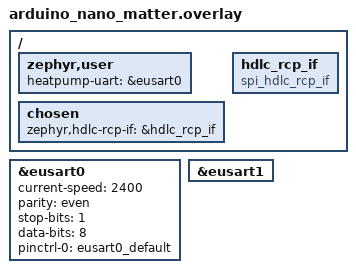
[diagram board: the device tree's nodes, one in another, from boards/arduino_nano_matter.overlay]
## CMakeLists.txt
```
# SPDX-License-Identifier: Apache-2.0

cmake_minimum_required(VERSION 3.20.0)

# Find Zephyr. This also loads Zephyr's build system.
find_package(Zephyr REQUIRED HINTS $ENV{ZEPHYR_BASE})

project(matter_cn105_controller VERSION 0.1.0)

# Add application source files
target_sources(app PRIVATE
    lib/HeatPump/heat_pump.h
    lib/HeatPump/heat_pump.cpp
    src/main.c
    src/heatpump_driver.cpp
    src/matter_integration.cpp
    src/state_sync.cpp
    src/attribute_handlers.cpp
    src/ot_error_stub.cpp
)

# Add include directories
target_include_directories(app PRIVATE
    include
    src
)

# TODO: Add Matter SDK library when integrating
# TODO: Add any additional dependencies
```

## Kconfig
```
# SPDX-License-Identifier: GPL-3.0-or-later
# Kconfig - Matter CN105 Heat Pump Controller configuration options

mainmenu "Matter CN105 Heat Pump Controller Configuration"

config APP_HEATPUMP_CN105
	bool "Enable CN105 Heat Pump Controller"
	default y
	help
	  Enable Mitsubishi heat pump controller via CN105 interface

if APP_HEATPUMP_CN105

config APP_HEATPUMP_UART_DEVICE
	string "UART device name for CN105"
	default "UART_1"
	help
	  UART device name for CN105 communication

config APP_HEATPUMP_SYNC_INTERVAL_MS
	int "Heat pump sync interval in milliseconds"
	default 5000
	help
	  Interval for syncing with heat pump

config APP_MATTER_ENABLED
	bool "Enable Matter integration"
	default y
	help
	  Enable Matter/CHIP protocol integration

endif # APP_HEATPUMP_CN105

source "Kconfig.zephyr"
```

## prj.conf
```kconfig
# SPDX-License-Identifier: Apache-2.0

# Zephyr Kernel Configuration
CONFIG_HEAP_MEM_POOL_SIZE=16384
CONFIG_MAIN_STACK_SIZE=2048
CONFIG_SYSTEM_WORKQUEUE_STACK_SIZE=2048

# Logging Configuration
CONFIG_LOG=y
CONFIG_LOG_DEFAULT_LEVEL=3
CONFIG_LOG_PRINTK=y
CONFIG_LOG_MODE_IMMEDIATE=y

CONFIG_LOG_MAX_LEVEL=1
CONFIG_LOG_MODE_MINIMAL=n
CONFIG_LOG_BACKEND_SPINEL=y
CONFIG_LOG_BACKEND_RTT=y
CONFIG_LOG_BACKEND_UART=n
CONFIG_BOOT_BANNER=n

# Serial/UART Configuration for CN105
CONFIG_SERIAL=y
CONFIG_UART_INTERRUPT_DRIVEN=y
CONFIG_UART_LINE_CTRL=y

# C++ Support
CONFIG_CPP=y
CONFIG_NEWLIB_LIBC=y

# Networking (for Matter/Thread)
CONFIG_NETWORKING=y
CONFIG_NET_IPV6=y
CONFIG_NET_UDP=y
CONFIG_NET_TCP=y
CONFIG_NET_L2_OPENTHREAD=y

# Disable certain parts of Zephyr IPv6 stack
CONFIG_NET_IPV6_NBR_CACHE=n
CONFIG_NET_IPV6_MLD=n

# Use HDLC RCP interface (host mode) for OpenThread
CONFIG_HDLC_RCP_IF=y
CONFIG_HDLC_RCP_IF_UART=y
CONFIG_OPENTHREAD_HDLC_RCP_IF_UART_RX_RING_BUFFER_SIZE=1024
CONFIG_OPENTHREAD_HDLC_RCP_IF_UART_TX_RING_BUFFER_SIZE=1024

# Basic OpenThread settings for quick bring-up
CONFIG_NET_CONFIG_SETTINGS=y
CONFIG_NET_CONFIG_IEEE802154_CHANNEL=26
CONFIG_NET_CONFIG_IEEE802154_PAN_ID=0x1234


# Optional: OT shell for debugging
# Uncomment if you want CLI at the Zephyr shell
# CONFIG_SHELL=y
# CONFIG_NET_SHELL=y
# CONFIG_OPENTHREAD_SHELL=y

# Thread Configuration (for Matter)
# TODO: Enable when Matter SDK is integrated
# CONFIG_NET_L2_OPENTHREAD=y
# CONFIG_OPENTHREAD_NORDIC_LIBRARY=y

# Matter SDK Configuration
# TODO: Enable when Matter SDK is integrated
# CONFIG_CHIP=y
# CONFIG_CHIP_PROJECT_CONFIG="matter_config.h"
# CONFIG_CHIP_DEVICE_VENDOR_ID=0xFFF1
# CONFIG_CHIP_DEVICE_PRODUCT_ID=0x8001

# Flash and Storage (for Matter credentials)
CONFIG_FLASH=y
CONFIG_FLASH_PAGE_LAYOUT=y
CONFIG_FLASH_MAP=y
CONFIG_NVS=y
CONFIG_SETTINGS=y
CONFIG_SETTINGS_NVS=y

# Increase memory for Matter stack
CONFIG_IDLE_STACK_SIZE=1024
CONFIG_ISR_STACK_SIZE=2048

# Debugging
CONFIG_DEBUG=y
CONFIG_THREAD_NAME=y
CONFIG_THREAD_MONITOR=y

# Console
CONFIG_CONSOLE=y
CONFIG_UART_CONSOLE=y

# Enable asserts for development
CONFIG_ASSERT=y
CONFIG_ASSERT_LEVEL=2
```

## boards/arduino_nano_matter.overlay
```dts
// SPDX-License-Identifier: GPL-3.0-or-later
/*
 * Device tree overlay for Arduino Nano Matter
 * Configures UART for CN105 heat pump communication
 */

/ {
	zephyr,user {
		heatpump-uart = &eusart0;
	};

	/* OpenThread HDLC RCP interface selection */
	chosen {
		/* Select the HDLC RCP network interface device */
		zephyr,hdlc-rcp-if = &hdlc_rcp_if;
	};

	/* Define the HDLC RCP interface device (SPI-based SPINEL) */
	hdlc_rcp_if: hdlc_rcp_if {
		compatible = "spi_hdlc_rcp_if";
		status = "okay";
	};
};

/* Configure UART for CN105 communication
 * Baud: 2400, 8 data bits, even parity, 1 stop bit (8E1)
 * Wired to Arduino UART0: TX=PA4 (D0), RX=PA5 (D1)
 */
&eusart0 {
	status = "okay";
	current-speed = <2400>;
	parity = "even";
	stop-bits = "1";
	data-bits = <8>;
	pinctrl-0 = <&eusart0_default>;
	pinctrl-names = "default";
};

/* Configure SPI for OpenThread RCP (SPINEL protocol)
 * Uses eusart1 as SPI bus with 4 MHz clock
 * CS: PC7 (active low)
 * Clock, MOSI, MISO: pins defined in eusart1_default pinctrl
 */
&eusart1 {
	status = "okay";
};
```

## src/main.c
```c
/**
 * @file main.c
 * @brief Main entry point for Matter CN105 Heat Pump Controller
 * 
 * This is the main application entry point for the Zephyr-based
 * Matter controller for Mitsubishi heat pumps via CN105 interface.
 */

#include <zephyr/kernel.h>
#include <zephyr/logging/log.h>
#include "heatpump_driver.h"

LOG_MODULE_REGISTER(main, CONFIG_LOG_DEFAULT_LEVEL);

/**
 * @brief Main application entry point
 * 
 * Initializes all subsystems:
 * - Heat pump driver (UART communication)
 * - Matter stack
 * - State synchronization
 * 
 * @return 0 on success, negative errno on failure
 */
int main(void)
{
    LOG_INF("Matter CN105 Heat Pump Controller starting...");
    LOG_INF("Version: 0.1.0");
    
    /* Initialize heat pump driver */
    LOG_INF("Initializing heat pump driver...");
    int ret = heatpump_init();
    if (ret) {
        LOG_ERR("heatpump_init failed: %d", ret);
    }
    ret = heatpump_connect();
    if (ret) {
        LOG_WRN("heatpump_connect pending/not ready: %d", ret);
    }
    
    /* TODO: Initialize Matter stack */
    LOG_INF("Initializing Matter stack...");
    
    /* TODO: Start state synchronization */
    LOG_INF("Starting state synchronization...");
    
    LOG_INF("Initialization complete");
    
    /* Main loop - handle events and maintain state sync */
    while (1) {
        /* Maintain CN105 link */
        heatpump_sync();
        
        /* Optionally, log status periodically */
        if (heatpump_is_connected()) {
            heatpump_status_t status;
            if (heatpump_get_status(&status) == 0) {
                LOG_DBG("HP: room=%.1fC operating=%d freq=%d",
                        (double)status.roomTemperature,
                        status.operating,
                        status.compressorFrequency);
            }
        }
        /* TODO: Process Matter attribute changes */
        /* TODO: Synchronize state between heat pump and Matter */
        
        k_sleep(K_MSEC(100));
    }
    
    return 0;
}
```

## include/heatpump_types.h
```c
/**
 * @file heatpump_types.h
 * @brief Data structures for Mitsubishi heat pump control
 * 
 * Based on the SwiCago/HeatPump library data structures
 * Adapted for use with Zephyr RTOS and Matter integration
 * 
 * Original library: https://github.com/SwiCago/HeatPump
 * License: GPL-3.0
 */

#ifndef HEATPUMP_TYPES_H
#define HEATPUMP_TYPES_H

#include <stdbool.h>

#ifdef __cplusplus
extern "C" {
#endif

/**
 * @brief Heat pump settings structure
 * 
 * Contains all user-configurable settings for the heat pump
 */
typedef struct {
    const char* power;        /**< Power state: "ON", "OFF" */
    const char* mode;         /**< Operating mode: "HEAT", "DRY", "COOL", "FAN", "AUTO" */
    float temperature;        /**< Target temperature in Celsius (16-31°C) */
    const char* fan;          /**< Fan speed: "AUTO", "QUIET", "1", "2", "3", "4" */
    const char* vane;         /**< Vertical vane position: "AUTO", "1", "2", "3", "4", "5", "SWING" */
    const char* wideVane;     /**< Horizontal vane position: "<<", "<", "|", ">", ">>", "<>", "SWING" */
    bool iSee;               /**< i-See sensor enabled/disabled */
    bool connected;          /**< Connection status with heat pump */
} heatpump_settings_t;

/**
 * @brief Heat pump status structure
 * 
 * Contains read-only status information from the heat pump
 */
typedef struct {
    float roomTemperature;       /**< Current room temperature in Celsius */
    bool operating;              /**< True if heat pump is actively heating/cooling */
    int compressorFrequency;     /**< Compressor frequency in Hz (0 when off) */
} heatpump_status_t;

/**
 * @brief Heat pump timers structure
 * 
 * Contains timer settings and status
 */
typedef struct {
    const char* mode;            /**< Timer mode: "NONE", "OFF", "ON", "BOTH" */
    int onMinutesSet;           /**< Minutes until ON timer activates (0 if not set) */
    int onMinutesRemaining;     /**< Minutes remaining for ON timer */
    int offMinutesSet;          /**< Minutes until OFF timer activates (0 if not set) */
    int offMinutesRemaining;    /**< Minutes remaining for OFF timer */
} heatpump_timers_t;

/**
 * @brief Heat pump operating modes enumeration
 */
typedef enum {
    HP_MODE_HEAT = 0,
    HP_MODE_DRY,
    HP_MODE_COOL,
    HP_MODE_FAN,
    HP_MODE_AUTO
} heatpump_mode_e;

/**
 * @brief Fan speed enumeration
 */
typedef enum {
    HP_FAN_AUTO = 0,
    HP_FAN_QUIET,
    HP_FAN_1,
    HP_FAN_2,
    HP_FAN_3,
    HP_FAN_4
} heatpump_fan_e;

/**
 * @brief Vane position enumeration
 */
typedef enum {
    HP_VANE_AUTO = 0,
    HP_VANE_1,
    HP_VANE_2,
    HP_VANE_3,
    HP_VANE_4,
    HP_VANE_5,
    HP_VANE_SWING
} heatpump_vane_e;

/**
 * @brief Wide vane (horizontal) position enumeration
 */
typedef enum {
    HP_WIDE_VANE_FAR_LEFT = 0,    /**< "<<" */
    HP_WIDE_VANE_LEFT,             /**< "<" */
    HP_WIDE_VANE_CENTER,           /**< "|" */
    HP_WIDE_VANE_RIGHT,            /**< ">" */
    HP_WIDE_VANE_FAR_RIGHT,        /**< ">>" */
    HP_WIDE_VANE_WIDE,             /**< "<>" */
    HP_WIDE_VANE_SWING             /**< "SWING" */
} heatpump_wide_vane_e;

/**
 * @brief Temperature limits
 */
#define HP_TEMP_MIN 16.0f
#define HP_TEMP_MAX 31.0f

/**
 * @brief Serial communication parameters for CN105
 */
#define HP_UART_BAUD_RATE 2400
#define HP_UART_DATA_BITS 8
#define HP_UART_PARITY_EVEN 1
#define HP_UART_STOP_BITS 1

#ifdef __cplusplus
}
#endif

#endif /* HEATPUMP_TYPES_H */
```

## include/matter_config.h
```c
/**
 * @file matter_config.h
 * @brief Matter/CHIP configuration for heat pump controller
 * 
 * Defines Matter cluster IDs, device types, and configuration
 * for integration with the Matter smart home protocol
 */

#ifndef MATTER_CONFIG_H
#define MATTER_CONFIG_H

#ifdef __cplusplus
extern "C" {
#endif

/**
 * @brief Matter Device Type
 * 
 * The heat pump is exposed as a Thermostat device type
 */
#define MATTER_DEVICE_TYPE_THERMOSTAT 0x0301

/**
 * @brief Standard Matter Cluster IDs
 */
#define MATTER_CLUSTER_IDENTIFY         0x0003  /**< Identify cluster */
#define MATTER_CLUSTER_ON_OFF           0x0006  /**< On/Off cluster */
#define MATTER_CLUSTER_DESCRIPTOR       0x001D  /**< Descriptor cluster */
#define MATTER_CLUSTER_THERMOSTAT       0x0201  /**< Thermostat cluster */
#define MATTER_CLUSTER_FAN_CONTROL      0x0202  /**< Fan Control cluster */
#define MATTER_CLUSTER_TEMP_MEASUREMENT 0x0402  /**< Temperature Measurement cluster */

/**
 * @brief Custom Vendor-Specific Cluster IDs
 * 
 * These clusters provide access to Mitsubishi-specific features
 * not available in standard Matter clusters.
 * 
 * Vendor ID range: 0xFFF1XXXX (example vendor ID)
 */
#define MATTER_CLUSTER_VANE_CONTROL     0xFFF1FC01  /**< Vertical vane control */
#define MATTER_CLUSTER_WIDE_VANE_CONTROL 0xFFF1FC02 /**< Horizontal vane control */
#define MATTER_CLUSTER_HP_STATUS        0xFFF1FC03  /**< Heat pump status information */
#define MATTER_CLUSTER_ISEE_CONTROL     0xFFF1FC04  /**< i-See sensor control */

/**
 * @brief Thermostat Cluster Attributes
 */
#define MATTER_ATTR_LOCAL_TEMPERATURE           0x0000  /**< Current room temperature */
#define MATTER_ATTR_OCCUPIED_COOLING_SETPOINT   0x0011  /**< Cooling setpoint */
#define MATTER_ATTR_OCCUPIED_HEATING_SETPOINT   0x0012  /**< Heating setpoint */
#define MATTER_ATTR_SYSTEM_MODE                 0x001C  /**< System mode (off/heat/cool/auto) */
#define MATTER_ATTR_THERMOSTAT_RUNNING_STATE    0x0029  /**< Running state */

/**
 * @brief Fan Control Cluster Attributes
 */
#define MATTER_ATTR_FAN_MODE                    0x0000  /**< Fan mode */
#define MATTER_ATTR_FAN_MODE_SEQUENCE           0x0001  /**< Fan mode sequence */
#define MATTER_ATTR_PERCENT_SETTING             0x0002  /**< Fan speed percentage */
#define MATTER_ATTR_PERCENT_CURRENT             0x0003  /**< Current fan speed percentage */

/**
 * @brief Thermostat System Mode Values
 */
#define MATTER_THERMOSTAT_MODE_OFF      0x00
#define MATTER_THERMOSTAT_MODE_AUTO     0x01
#define MATTER_THERMOSTAT_MODE_COOL     0x03
#define MATTER_THERMOSTAT_MODE_HEAT     0x04
#define MATTER_THERMOSTAT_MODE_DRY      0x08  /**< Precool/Dehumidify */
#define MATTER_THERMOSTAT_MODE_FAN_ONLY 0x07

/**
 * @brief Fan Mode Values
 */
#define MATTER_FAN_MODE_OFF    0x00
#define MATTER_FAN_MODE_LOW    0x01
#define MATTER_FAN_MODE_MEDIUM 0x02
#define MATTER_FAN_MODE_HIGH   0x03
#define MATTER_FAN_MODE_ON     0x04
#define MATTER_FAN_MODE_AUTO   0x05
#define MATTER_FAN_MODE_SMART  0x06

/**
 * @brief Matter Endpoint Configuration
 */
#define MATTER_ENDPOINT_ROOT        0   /**< Root endpoint */
#define MATTER_ENDPOINT_THERMOSTAT  1   /**< Thermostat endpoint */

/**
 * @brief Temperature Conversion Macros
 * 
 * Matter uses temperature in units of 0.01°C (hundredths of degrees)
 */
#define CELSIUS_TO_MATTER_TEMP(temp) ((int16_t)((temp) * 100))
#define MATTER_TEMP_TO_CELSIUS(temp) ((float)(temp) / 100.0f)

/**
 * @brief Default Configuration Values
 */
#define DEFAULT_MIN_SETPOINT_CELSIUS    16.0f   /**< Minimum temperature setpoint */
#define DEFAULT_MAX_SETPOINT_CELSIUS    31.0f   /**< Maximum temperature setpoint */
#define DEFAULT_SETPOINT_CELSIUS        22.0f   /**< Default temperature setpoint */

/**
 * @brief Matter Stack Configuration
 * 
 * TODO: These values need to be tuned based on actual testing
 */
#define MATTER_THREAD_STACK_SIZE    4096    /**< Matter task stack size */
#define MATTER_THREAD_PRIORITY      5       /**< Matter task priority */

/**
 * @brief Update Intervals (milliseconds)
 */
#define HP_STATUS_UPDATE_INTERVAL_MS    5000    /**< Status polling interval */
#define HP_SETTINGS_UPDATE_INTERVAL_MS  1000    /**< Settings update interval */

/* Configuration placeholders for future implementation */
/* TODO: Implement actual Matter integration */
/* TODO: Add commissioning configuration */
/* TODO: Add network credential storage configuration */
/* TODO: Add OTA update configuration */
/* TODO: Add factory reset configuration */

#ifdef __cplusplus
}
#endif

#endif /* MATTER_CONFIG_H */
```

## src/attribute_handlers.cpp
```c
/**
 * @file attribute_handlers.cpp
 * @brief Matter attribute read/write handlers
 * 
 * Handles Matter cluster attribute operations and converts
 * between Matter data formats and heat pump formats.
 */

#include <zephyr/kernel.h>
#include <zephyr/logging/log.h>
#include "matter_config.h"
#include "heatpump_driver.h"

LOG_MODULE_REGISTER(attribute_handlers, CONFIG_LOG_DEFAULT_LEVEL);

/**
 * @brief Handle thermostat system mode attribute write
 * 
 * Converts Matter thermostat mode to heat pump mode and applies
 */
int handle_thermostat_mode_write(uint8_t mode)
{
    const char *hp_mode = NULL;
    
    /* Convert Matter mode to heat pump mode */
    switch (mode) {
        case MATTER_THERMOSTAT_MODE_OFF:
            return heatpump_set_power("OFF");
        
        case MATTER_THERMOSTAT_MODE_HEAT:
            hp_mode = "HEAT";
            break;
        
        case MATTER_THERMOSTAT_MODE_COOL:
            hp_mode = "COOL";
            break;
        
        case MATTER_THERMOSTAT_MODE_AUTO:
            hp_mode = "AUTO";
            break;
        
        case MATTER_THERMOSTAT_MODE_DRY:
            hp_mode = "DRY";
            break;
        
        case MATTER_THERMOSTAT_MODE_FAN_ONLY:
            hp_mode = "FAN";
            break;
        
        default:
            LOG_ERR("Unsupported thermostat mode: %d", mode);
            return -EINVAL;
    }
    
    /* Ensure power is on */
    heatpump_set_power("ON");
    
    /* Set the mode */
    return heatpump_set_mode(hp_mode);
}

/**
 * @brief Handle temperature setpoint attribute write
 * 
 * Converts Matter temperature (0.01°C units) to Celsius
 */
int handle_temperature_setpoint_write(int16_t matter_temp)
{
    float celsius = MATTER_TEMP_TO_CELSIUS(matter_temp);
    
    /* Validate temperature range */
    if (celsius < HP_TEMP_MIN || celsius > HP_TEMP_MAX) {
        LOG_ERR("Temperature out of range: %.1f°C", static_cast<double>(celsius));
        return -EINVAL;
    }
    
    return heatpump_set_temperature(celsius);
}

/**
 * @brief Handle fan mode attribute write
 * 
 * Converts Matter fan mode to heat pump fan setting
 */
int handle_fan_mode_write(uint8_t mode)
{
    const char *hp_fan = NULL;
    
    /* Convert Matter fan mode to heat pump fan */
    switch (mode) {
        case MATTER_FAN_MODE_OFF:
            hp_fan = "QUIET";  /* Map OFF to QUIET */
            break;
        
        case MATTER_FAN_MODE_LOW:
            hp_fan = "1";
            break;
        
        case MATTER_FAN_MODE_MEDIUM:
            hp_fan = "2";
            break;
        
        case MATTER_FAN_MODE_HIGH:
            hp_fan = "4";
            break;
        
        case MATTER_FAN_MODE_AUTO:
            hp_fan = "AUTO";
            break;
        
        default:
            LOG_ERR("Unsupported fan mode: %d", mode);
            return -EINVAL;
    }
    
    return heatpump_set_fan(hp_fan);
}

/**
 * @brief Read thermostat local temperature attribute
 * 
 * Returns current room temperature from heat pump
 */
int handle_local_temperature_read(int16_t *matter_temp)
{
    heatpump_status_t status;
    
    if (heatpump_get_status(&status) != 0) {
        return -EIO;
    }
    
    *matter_temp = CELSIUS_TO_MATTER_TEMP(status.roomTemperature);
    return 0;
}

/**
 * @brief Read thermostat running state attribute
 * 
 * Returns whether heat pump is actively heating/cooling
 */
int handle_running_state_read(uint16_t *state)
{
    heatpump_status_t status;
    
    if (heatpump_get_status(&status) != 0) {
        return -EIO;
    }
    
    /* TODO: Map heat pump operating state to Matter running state bits */
    *state = status.operating ? 0x0001 : 0x0000;
    
    return 0;
}

/**
 * @brief Handle custom vane control attribute write
 * 
 * Controls vertical vane position
 */
int handle_vane_position_write(uint8_t position)
{
    const char *vane = NULL;
    
    /* Map position to vane string */
    switch (position) {
        case 0: vane = "AUTO"; break;
        case 1: vane = "1"; break;
        case 2: vane = "2"; break;
        case 3: vane = "3"; break;
        case 4: vane = "4"; break;
        case 5: vane = "5"; break;
        case 6: vane = "SWING"; break;
        default:
            LOG_ERR("Invalid vane position: %d", position);
            return -EINVAL;
    }
    
    return heatpump_set_vane(vane);
}

/**
 * @brief Handle custom wide vane control attribute write
 * 
 * Controls horizontal vane position
 */
int handle_wide_vane_position_write(uint8_t position)
{
    const char *wide_vane = NULL;
    
    /* Map position to wide vane string */
    switch (position) {
        case 0: wide_vane = "<<"; break;
        case 1: wide_vane = "<"; break;
        case 2: wide_vane = "|"; break;
        case 3: wide_vane = ">"; break;
        case 4: wide_vane = ">>"; break;
        case 5: wide_vane = "<>"; break;
        case 6: wide_vane = "SWING"; break;
        default:
            LOG_ERR("Invalid wide vane position: %d", position);
            return -EINVAL;
    }
    
    return heatpump_set_wide_vane(wide_vane);
}
```

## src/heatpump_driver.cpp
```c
/**
 * @file heatpump_driver.cpp
 * @brief Heat pump driver implementation for CN105 communication
 * 
 * This file will contain the adaptation of the SwiCago/HeatPump library
 * for use with Zephyr RTOS.
 * 
 * Original library: https://github.com/SwiCago/HeatPump
 * License: GPL-3.0
 */

#include "heatpump_driver.h"
#include <zephyr/kernel.h>
#include <zephyr/drivers/uart.h>
#include <zephyr/device.h>
#include <zephyr/devicetree.h>
#include "../lib/HeatPump/heat_pump.h"
#include <zephyr/logging/log.h>

LOG_MODULE_REGISTER(heatpump_driver, CONFIG_LOG_DEFAULT_LEVEL);

/* Thread configuration */
#define HEATPUMP_THREAD_STACK_SIZE 2048
#define HEATPUMP_THREAD_PRIORITY   5
#define HEATPUMP_UPDATE_INTERVAL_MS 100  /* Poll heat pump every 100ms */

/* Memory slab configuration for packet buffers */
#define PACKET_BUFFER_SIZE  64  /* Max packet size is 22 bytes, rounded to 64 for alignment */
#define NUM_PACKET_BUFFERS  4   /* Pre-allocate 4 packet buffers for concurrent operations */

/**
 * @brief Packet buffer structure for memory slab
 *
 * Provides a predictable memory layout for efficient allocation.
 */
struct packet_buffer {
    uint8_t data[PACKET_BUFFER_SIZE];
    size_t length;
};

/* Define and initialize the packet buffer memory slab */
K_MEM_SLAB_DEFINE(packet_slab, sizeof(struct packet_buffer), NUM_PACKET_BUFFERS, 4);

/* Static variables for driver state */
static heatpump_settings_t current_settings;
static heatpump_status_t current_status;
static heatpump_timers_t current_timers;
static bool connected = false;

/* Callback functions */
static heatpump_settings_callback_t settings_callback = NULL;
static heatpump_status_callback_t status_callback = NULL;

/* UART device (assigned when CN105 transport is implemented) */
static const struct device *uart_dev;
static HeatPump s_hp;

/* Thread management */
static struct k_thread heatpump_thread_data;
static k_tid_t heatpump_thread_id = NULL;
static bool heatpump_thread_running = false;
static K_THREAD_STACK_DEFINE(heatpump_stack, HEATPUMP_THREAD_STACK_SIZE);

/* Forward declarations for HeatPump library callbacks */
static void hp_on_connect_callback(void);
static void hp_settings_changed_callback(void);
static void hp_status_changed_callback(heatpumpStatus newStatus);
static void hp_packet_callback(uint8_t* packet, unsigned int length, char* packetDirection);
static void hp_room_temp_changed_callback(float currentRoomTemperature);
/**
 * @brief HeatPump library callback: Connection established
 * 
 * Called when the heat pump handshake is successful
 */
static void hp_on_connect_callback(void)
{
    LOG_INF("Heat pump connected");
    connected = true;
}

/**
 * @brief HeatPump library callback: Settings changed
 * 
 * Called when the heat pump settings change
 */
static void hp_settings_changed_callback(void)
{
    LOG_INF("Heat pump settings changed");
    
    /* Update local cache */
    heatpumpSettings hp = s_hp.getSettings();
    current_settings.power = hp.power;
    current_settings.mode = hp.mode;
    current_settings.temperature = hp.temperature;
    current_settings.fan = hp.fan;
    current_settings.vane = hp.vane;
    current_settings.wideVane = hp.wideVane;
    current_settings.iSee = hp.iSee;
    current_settings.connected = connected;
    
    /* Call registered application callback if present */
    if (settings_callback) {
        settings_callback(current_settings);
    }
}

/**
 * @brief HeatPump library callback: Status changed
 * 
 * Called when the heat pump status changes
 * 
 * @param newStatus The new status from the heat pump
 */
static void hp_status_changed_callback(heatpumpStatus newStatus)
{
    LOG_INF("Heat pump status changed");
    
    /* Update local cache */
    current_status.roomTemperature = newStatus.roomTemperature;
    current_status.operating = newStatus.operating;
    current_status.compressorFrequency = newStatus.compressorFrequency;
    
    /* Update timers as well */
    current_timers.mode = newStatus.timers.mode;
    current_timers.onMinutesSet = newStatus.timers.onMinutesSet;
    current_timers.onMinutesRemaining = newStatus.timers.onMinutesRemaining;
    current_timers.offMinutesSet = newStatus.timers.offMinutesSet;
    current_timers.offMinutesRemaining = newStatus.timers.offMinutesRemaining;
    
    /* Call registered application callback if present */
    if (status_callback) {
        status_callback(current_status);
    }
}

/**
 * @brief HeatPump library callback: Packet transmitted or received
 * 
 * Called for debug/logging purposes when packets are sent or received
 * 
 * @param packet The packet data
 * @param length The packet length
 * @param packetDirection Direction indicator ("packetSent" or "packetRecv")
 */
static void hp_packet_callback(uint8_t* packet, unsigned int length, char* packetDirection)
{
    if (packet && length > 0 && packetDirection) {
        LOG_DBG("Heat pump packet %s: %d bytes", packetDirection, length);
        /* Could log hex dump here for deeper debugging if needed */
    }
}

/**
 * @brief HeatPump library callback: Room temperature changed
 * 
 * Called when the room temperature reading changes
 * 
 * @param currentRoomTemperature The new room temperature
 */
static void hp_room_temp_changed_callback(float currentRoomTemperature)
{
    LOG_INF("Room temperature: %.1f°C", (double)currentRoomTemperature);
    current_status.roomTemperature = currentRoomTemperature;
    
    /* Call registered application callback if present */
    if (status_callback) {
        status_callback(current_status);
    }
}

/**
 * @brief Heatpump update thread
 * 
 * This thread runs periodically to:
 * - Transmit pending commands to the heat pump
 * - Read responses from the heat pump
 * - Invoke callbacks when state changes occur
 * 
 * This replaces the Arduino loop() paradigm with Zephyr threading
 * 
 * @param arg1 Unused argument (required by k_thread_create)
 * @param arg2 Unused argument (required by k_thread_create)
 * @param arg3 Unused argument (required by k_thread_create)
 */
static void heatpump_update_thread(void *arg1, void *arg2, void *arg3)
{
    ARG_UNUSED(arg1);
    ARG_UNUSED(arg2);
    ARG_UNUSED(arg3);
    
    LOG_INF("Heat pump update thread started");
    heatpump_thread_running = true;
    
    /* Main update loop */
    while (heatpump_thread_running) {
        /* Call the HeatPump library's update method */
        /* This method handles:
         * - Sending queued commands
         * - Reading responses
         * - Triggering registered callbacks
         */
        if (s_hp.update()) {
            /* Update was successful */
            LOG_DBG("Heat pump update completed");
        }
        
        /* Sleep for the configured update interval */
        k_msleep(HEATPUMP_UPDATE_INTERVAL_MS);
    }
    
    LOG_INF("Heat pump update thread stopped");
}

/**

 * @brief Initialize the heat pump driver
 */
int heatpump_init(void)
{
    LOG_INF("Initializing heat pump driver");
    
#if DT_HAS_CHOSEN(heatpump_uart)
    uart_dev = DEVICE_DT_GET(DT_CHOSEN(heatpump_uart));
#else
    uart_dev = DEVICE_DT_GET(DT_NODELABEL(eusart0));
#endif
    if (!device_is_ready(uart_dev)) {
        LOG_ERR("Heatpump UART device not ready");
        return -ENODEV;
    }
    if (!s_hp.connect(uart_dev, HP_UART_BAUD_RATE)) {
        LOG_ERR("Heat pump handshake failed");
        return -EIO;
    }
    connected = s_hp.isConnected();
    
    /* Initialize settings to default values */
    current_settings.power = "OFF";
    current_settings.mode = "AUTO";
    current_settings.temperature = 22.0f;
    current_settings.fan = "AUTO";
    current_settings.vane = "AUTO";
    current_settings.wideVane = "|";
    current_settings.iSee = false;
    current_settings.connected = false;
    
    /* Initialize status */
    current_status.roomTemperature = 20.0f;
    current_status.operating = false;
    current_status.compressorFrequency = 0;
    
    /* Initialize timers */
    current_timers.mode = "NONE";
    current_timers.onMinutesSet = 0;
    current_timers.onMinutesRemaining = 0;
    current_timers.offMinutesSet = 0;
    current_timers.offMinutesRemaining = 0;
    
    /* Register HeatPump library callbacks for Zephyr integration */
    s_hp.setOnConnectCallback(hp_on_connect_callback);
    s_hp.setSettingsChangedCallback(hp_settings_changed_callback);
    s_hp.setStatusChangedCallback(hp_status_changed_callback);
    s_hp.setPacketCallback(hp_packet_callback);
    s_hp.setRoomTempChangedCallback(hp_room_temp_changed_callback);
    
    /* Start the heat pump update thread */
    heatpump_thread_id = k_thread_create(&heatpump_thread_data,
                                         heatpump_stack,
                                         HEATPUMP_THREAD_STACK_SIZE,
                                         heatpump_update_thread,
                                         NULL, NULL, NULL,
                                         HEATPUMP_THREAD_PRIORITY,
                                         0,
                                         K_NO_WAIT);
    
    if (heatpump_thread_id == NULL) {
        LOG_ERR("Failed to create heat pump update thread");
        return -EAGAIN;
    }
    
    k_thread_name_set(heatpump_thread_id, "heatpump");
    
    LOG_INF("Heat pump driver initialized");
    return 0;
}

/**
 * @brief Shutdown the heat pump driver
 *
 * Stops the update thread and cleans up resources
 *
 * @return 0 on success, negative errno on failure
 */
int heatpump_shutdown(void)
{
    LOG_INF("Shutting down heat pump driver");
    
    if (heatpump_thread_id != NULL) {
        /* Signal the thread to stop */
        heatpump_thread_running = false;
        
        /* Wait for thread to complete (with timeout) */
        int ret = k_thread_join(heatpump_thread_id, K_MSEC(5000));
        if (ret != 0) {
            LOG_WRN("Heat pump thread did not exit cleanly, forcing abort");
            k_thread_abort(heatpump_thread_id);
        }
        
        heatpump_thread_id = NULL;
    }
    
    LOG_INF("Heat pump driver shutdown complete");
    return 0;
}

/**
 * @brief Connect to the heat pump
 */
int heatpump_connect(void)
{
    LOG_INF("Connecting to heat pump...");
    if (!device_is_ready(uart_dev)) {
        return -ENODEV;
    }
    if (!s_hp.connect(uart_dev, HP_UART_BAUD_RATE)) {
        return -EIO;
    }
    connected = s_hp.isConnected();
    return connected ? 0 : -EIO;
}

/**
 * @brief Synchronize with the heat pump
 */
void heatpump_sync(void)
{
    s_hp.sync();
}

/**
 * @brief Get current heat pump settings
 */
int heatpump_get_settings(heatpump_settings_t *settings)
{
    if (settings == NULL) {
        return -EINVAL;
    }
    heatpumpSettings hp = s_hp.getSettings();
    settings->power = hp.power;
    settings->mode = hp.mode;
    settings->temperature = hp.temperature;
    settings->fan = hp.fan;
    settings->vane = hp.vane;
    settings->wideVane = hp.wideVane;
    settings->iSee = hp.iSee;
    settings->connected = connected;
    return 0;
}

/**
 * @brief Get current heat pump status
 */
int heatpump_get_status(heatpump_status_t *status)
{
    if (status == NULL) {
        return -EINVAL;
    }
    heatpumpStatus s = s_hp.getStatus();
    status->roomTemperature = s.roomTemperature;
    status->operating = s.operating;
    status->compressorFrequency = s.compressorFrequency;
    return 0;
}

/**
 * @brief Get current heat pump timers
 */
int heatpump_get_timers(heatpump_timers_t *timers)
{
    if (timers == NULL) {
        return -EINVAL;
    }
    /* The library exposes timers via getStatus parsing; no direct method */
    heatpumpStatus s = s_hp.getStatus();
    (void)s;
    *timers = current_timers;
    return 0;
}

/**
 * @brief Set power state
 */
int heatpump_set_power(const char *power)
{
    LOG_INF("Setting power: %s", power);
    s_hp.setPowerSetting((power && power[0] == 'O' && power[1] == 'N') ? true : false);
    return s_hp.update() ? 0 : -EIO;
}

/**
 * @brief Set operating mode
 */
int heatpump_set_mode(const char *mode)
{
    LOG_INF("Setting mode: %s", mode);
    s_hp.setModeSetting(mode);
    return s_hp.update() ? 0 : -EIO;
}

/**
 * @brief Set target temperature
 */
int heatpump_set_temperature(float temperature)
{
    LOG_INF("Setting temperature: %.1f°C", (double)temperature);
    s_hp.setTemperature(temperature);
    return s_hp.update() ? 0 : -EIO;
}

/**
 * @brief Set fan speed
 */
int heatpump_set_fan(const char *fan)
{
    LOG_INF("Setting fan: %s", fan);
    s_hp.setFanSpeed(fan);
    return s_hp.update() ? 0 : -EIO;
}

/**
 * @brief Set vertical vane position
 */
int heatpump_set_vane(const char *vane)
{
    LOG_INF("Setting vane: %s", vane);
    s_hp.setVaneSetting(vane);
    return s_hp.update() ? 0 : -EIO;
}

/**
 * @brief Set horizontal vane position
 */
int heatpump_set_wide_vane(const char *wide_vane)
{
    LOG_INF("Setting wide vane: %s", wide_vane);
    s_hp.setWideVaneSetting(wide_vane);
    return s_hp.update() ? 0 : -EIO;
}

/**
 * @brief Update all settings at once
 */
int heatpump_update_settings(const heatpump_settings_t *settings)
{
    if (settings == NULL) {
        return -EINVAL;
    }
    LOG_INF("Updating all settings");
    heatpumpSettings s;
    s.power = settings->power;
    s.mode = settings->mode;
    s.temperature = settings->temperature;
    s.fan = settings->fan;
    s.vane = settings->vane;
    s.wideVane = settings->wideVane;
    s_hp.setSettings(s);
    return s_hp.update() ? 0 : -EIO;
}

/**
 * @brief Register callback for settings changes
 */
void heatpump_set_settings_callback(heatpump_settings_callback_t callback)
{
    settings_callback = callback;
}

/**
 * @brief Register callback for status changes
 */
void heatpump_set_status_callback(heatpump_status_callback_t callback)
{
    status_callback = callback;
}

/**
 * @brief Check if connected to heat pump
 */
bool heatpump_is_connected(void)
{
    return s_hp.isConnected();
}
```

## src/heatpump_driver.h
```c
/**
 * @file heatpump_driver.h
 * @brief Heat pump driver interface for CN105 communication
 *
 * Provides the API for communicating with Mitsubishi heat pumps
 * via the CN105 connector. Based on the SwiCago/HeatPump library.
 *
 * @section memory Memory Management
 *
 * This driver uses Zephyr memory pools for efficient packet buffer allocation:
 * - Pre-allocated pool of 4 x 64-byte buffers
 * - Predictable allocation latency (no fragmentation)
 * - Suitable for real-time UART communication
 *
 * @section threading Threading Model
 *
 * Runs a dedicated Zephyr thread for periodic heat pump polling:
 * - Update interval: 100ms (configurable)
 * - Priority: 5 (configurable)
 * - Stack size: 2048 bytes (configurable)
 * - Callbacks invoked from this thread context
 */

#ifndef HEATPUMP_DRIVER_H
#define HEATPUMP_DRIVER_H

#include "heatpump_types.h"
#include <zephyr/kernel.h>

#ifdef __cplusplus
extern "C" {
#endif

/**
 * @brief Callback function type for settings updates
 * 
 * Called when the heat pump settings change
 */
typedef void (*heatpump_settings_callback_t)(heatpump_settings_t settings);

/**
 * @brief Callback function type for status updates
 * 
 * Called when the heat pump status changes
 */
typedef void (*heatpump_status_callback_t)(heatpump_status_t status);

/**
 * @brief Initialize the heat pump driver
 * 
 * Sets up UART communication with the heat pump via CN105,
 * initializes memory pools, and starts the periodic update thread.
 * 
 * @return 0 on success, negative errno on failure
 */
int heatpump_init(void);

/**
 * @brief Shutdown the heat pump driver
 *
 * Stops the update thread and cleans up resources
 *
 * @return 0 on success, negative errno on failure
 */
int heatpump_shutdown(void);

/**
 * @brief Connect to the heat pump
 * 
 * Establishes communication and performs initial handshake
 * 
 * @return 0 on success, negative errno on failure
 */
int heatpump_connect(void);

/**
 * @brief Synchronize with the heat pump
 * 
 * Sends sync packets and waits for response
 * Should be called periodically to maintain connection
 */
void heatpump_sync(void);

/**
 * @brief Get current heat pump settings
 * 
 * @param settings Pointer to settings structure to fill
 * @return 0 on success, negative errno on failure
 */
int heatpump_get_settings(heatpump_settings_t *settings);

/**
 * @brief Get current heat pump status
 * 
 * @param status Pointer to status structure to fill
 * @return 0 on success, negative errno on failure
 */
int heatpump_get_status(heatpump_status_t *status);

/**
 * @brief Get current heat pump timers
 * 
 * @param timers Pointer to timers structure to fill
 * @return 0 on success, negative errno on failure
 */
int heatpump_get_timers(heatpump_timers_t *timers);

/**
 * @brief Set power state
 * 
 * @param power Power state: "ON" or "OFF"
 * @return 0 on success, negative errno on failure
 */
int heatpump_set_power(const char *power);

/**
 * @brief Set operating mode
 * 
 * @param mode Mode: "HEAT", "DRY", "COOL", "FAN", "AUTO"
 * @return 0 on success, negative errno on failure
 */
int heatpump_set_mode(const char *mode);

/**
 * @brief Set target temperature
 * 
 * @param temperature Temperature in Celsius (16-31°C)
 * @return 0 on success, negative errno on failure
 */
int heatpump_set_temperature(float temperature);

/**
 * @brief Set fan speed
 * 
 * @param fan Fan speed: "AUTO", "QUIET", "1", "2", "3", "4"
 * @return 0 on success, negative errno on failure
 */
int heatpump_set_fan(const char *fan);

/**
 * @brief Set vertical vane position
 * 
 * @param vane Vane position: "AUTO", "1"-"5", "SWING"
 * @return 0 on success, negative errno on failure
 */
int heatpump_set_vane(const char *vane);

/**
 * @brief Set horizontal vane position
 * 
 * @param wide_vane Wide vane position: "<<", "<", "|", ">", ">>", "<>", "SWING"
 * @return 0 on success, negative errno on failure
 */
int heatpump_set_wide_vane(const char *wide_vane);

/**
 * @brief Update all settings at once
 * 
 * More efficient than calling individual setters
 * 
 * @param settings Settings structure to apply
 * @return 0 on success, negative errno on failure
 */
int heatpump_update_settings(const heatpump_settings_t *settings);

/**
 * @brief Register callback for settings changes
 * 
 * @param callback Function to call when settings change
 */
void heatpump_set_settings_callback(heatpump_settings_callback_t callback);

/**
 * @brief Register callback for status changes
 * 
 * @param callback Function to call when status changes
 */
void heatpump_set_status_callback(heatpump_status_callback_t callback);

/**
 * @brief Check if connected to heat pump
 * 
 * @return true if connected, false otherwise
 */
bool heatpump_is_connected(void);

/**
 * @section pool_config Memory Pool Configuration
 *
 * The driver uses a Zephyr memory pool for packet buffer allocation.
 * Configuration parameters in heatpump_driver.cpp:
 *
 * - PACKET_BUFFER_SIZE: Size of each buffer (default 64 bytes)
 * - NUM_PACKET_BUFFERS: Number of pre-allocated buffers (default 4)
 *
 * To customize these values:
 * 1. Edit the #define values in heatpump_driver.cpp
 * 2. Adjust based on your application's packet throughput
 * 3. Monitor with pool statistics via logging/debug interface
 *
 * Benefits of memory pools:
 * - Deterministic allocation time (O(1))
 * - No fragmentation
 * - No malloc/free overhead
 * - Real-time safe
 */

#ifdef __cplusplus
}
#endif

#endif /* HEATPUMP_DRIVER_H */
```

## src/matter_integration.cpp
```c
/**
 * @file matter_integration.cpp
 * @brief Matter stack integration for heat pump controller
 * 
 * Integrates the Matter (formerly CHIP) protocol stack with the
 * heat pump driver to expose the device as a Matter thermostat.
 */

#include <zephyr/kernel.h>
#include <zephyr/logging/log.h>
#include "matter_config.h"
#include "heatpump_driver.h"

LOG_MODULE_REGISTER(matter_integration, CONFIG_LOG_DEFAULT_LEVEL);

/**
 * @brief Initialize Matter stack
 * 
 * Sets up Matter server, registers endpoints, and configures clusters
 * 
 * @return 0 on success, negative errno on failure
 */
int matter_init(void)
{
    LOG_INF("Initializing Matter stack");
    
    /* TODO: Initialize Matter/CHIP stack */
    /* TODO: Set up thermostat device type */
    /* TODO: Register standard clusters:
     *       - Identify
     *       - On/Off
     *       - Thermostat
     *       - Fan Control
     *       - Temperature Measurement
     */
    /* TODO: Register custom vendor clusters:
     *       - Vane Control
     *       - Wide Vane Control
     *       - Heat Pump Status
     *       - i-See Control
     */
    
    LOG_WRN("Matter initialization not yet implemented");
    return -ENOSYS;
}

/**
 * @brief Start Matter server
 * 
 * Starts the Matter server and begins advertising for commissioning
 * 
 * @return 0 on success, negative errno on failure
 */
int matter_start(void)
{
    LOG_INF("Starting Matter server");
    
    /* TODO: Start Matter server */
    /* TODO: Begin commissioning advertisement */
    
    LOG_WRN("Matter start not yet implemented");
    return -ENOSYS;
}

/**
 * @brief Handle Matter commissioning
 * 
 * Processes commissioning requests and manages device pairing
 * 
 * @return 0 on success, negative errno on failure
 */
int matter_handle_commissioning(void)
{
    /* TODO: Implement commissioning logic */
    /* TODO: Handle QR code / manual pairing code generation */
    /* TODO: Process commissioning steps */
    
    return -ENOSYS;
}

/**
 * @brief Update Matter attributes from heat pump state
 * 
 * Synchronizes Matter cluster attributes with current heat pump state
 * 
 * @return 0 on success, negative errno on failure
 */
int matter_update_attributes(void)
{
    heatpump_settings_t settings;
    heatpump_status_t status;
    
    /* Get current heat pump state */
    if (heatpump_get_settings(&settings) != 0) {
        LOG_ERR("Failed to get heat pump settings");
        return -EIO;
    }
    
    if (heatpump_get_status(&status) != 0) {
        LOG_ERR("Failed to get heat pump status");
        return -EIO;
    }
    
    /* TODO: Update Matter thermostat attributes */
    /* TODO: Update Matter fan control attributes */
    /* TODO: Update Matter custom cluster attributes */
    
    return -ENOSYS;
}

/**
 * @brief Process Matter attribute write requests
 * 
 * Called when Matter controller writes to device attributes
 * Updates heat pump settings accordingly
 * 
 * @return 0 on success, negative errno on failure
 */
int matter_process_attribute_writes(void)
{
    /* TODO: Check for pending attribute write operations */
    /* TODO: Validate attribute values */
    /* TODO: Update heat pump via heatpump_driver */
    /* TODO: Confirm attribute changes */
    
    return -ENOSYS;
}
```

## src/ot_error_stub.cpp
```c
// Minimal stub to satisfy link: otThreadErrorToString, otPlatLog, otPlatUartSend, and platformUartPanic
// This should be replaced by OpenThread's implementation once OT config is corrected.
#include <openthread/error.h>
#include <openthread/platform/logging.h>
#include <stdarg.h>
#include <stdio.h>
#include <stdint.h>
#include <stddef.h>

extern "C" const char *otThreadErrorToString(otError /*aError*/) {
    return "OT error";
}

extern "C" void otPlatLog(otLogLevel aLogLevel, otLogRegion aLogRegion, const char *aFormat, ...) {
    // Platform-specific logging implementation
    // This stub forwards to standard output
    (void)aLogLevel;
    (void)aLogRegion;

    va_list args;
    va_start(args, aFormat);
    vprintf(aFormat, args);
    va_end(args);
    printf("\n");
}

extern "C" void otPlatUartSend(const uint8_t *aBuf, uint16_t aBufLength) {
    // Platform-specific UART send for Spinel protocol
    // This stub outputs to stdout
    if (aBuf && aBufLength > 0) {
        fwrite(aBuf, 1, aBufLength, stdout);
        fflush(stdout);
    }
}

extern "C" void platformUartPanic(void) {
    // Called in panic mode to prepare UART for raw output
    // This is a no-op stub
}
```

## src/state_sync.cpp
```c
/**
 * @file state_sync.cpp
 * @brief State synchronization between heat pump and Matter
 * 
 * Manages bidirectional synchronization of state between the
 * physical heat pump and the Matter virtual device.
 */

#include <zephyr/kernel.h>
#include <zephyr/logging/log.h>
#include "heatpump_driver.h"
#include "matter_config.h"

LOG_MODULE_REGISTER(state_sync, CONFIG_LOG_DEFAULT_LEVEL);

/* Synchronization flags */
static bool sync_in_progress = false;

/**
 * @brief Callback for heat pump settings changes
 * 
 * Called by the heat pump driver when settings change
 * (either from physical controls or IR remote)
 */
static void on_heatpump_settings_changed(heatpump_settings_t settings)
{
    LOG_INF("Heat pump settings changed");
    
    /* TODO: Update Matter attributes to reflect new settings */
    /* TODO: This ensures Matter state stays in sync with physical device */
}

/**
 * @brief Callback for heat pump status changes
 * 
 * Called by the heat pump driver when status changes
 */
static void on_heatpump_status_changed(heatpump_status_t status)
{
    const double temp_c = static_cast<double>(status.roomTemperature);
    LOG_DBG("Heat pump status changed: temp=%.1f°C, operating=%d",
            temp_c, status.operating);
    
    /* TODO: Update Matter temperature measurement */
    /* TODO: Update Matter running state */
}

/**
 * @brief Initialize state synchronization
 * 
 * Sets up callbacks and synchronization timers
 * 
 * @return 0 on success, negative errno on failure
 */
int state_sync_init(void)
{
    LOG_INF("Initializing state synchronization");
    
    /* Register callbacks with heat pump driver */
    heatpump_set_settings_callback(on_heatpump_settings_changed);
    heatpump_set_status_callback(on_heatpump_status_changed);
    
    /* TODO: Set up periodic sync timer */
    
    LOG_INF("State synchronization initialized");
    return 0;
}

/**
 * @brief Synchronize state from heat pump to Matter
 * 
 * Reads current heat pump state and updates Matter attributes
 * 
 * @return 0 on success, negative errno on failure
 */
int state_sync_hp_to_matter(void)
{
    if (sync_in_progress) {
        LOG_WRN("Sync already in progress");
        return -EBUSY;
    }
    
    sync_in_progress = true;
    
    /* TODO: Read heat pump settings and status */
    /* TODO: Update Matter cluster attributes */
    /* TODO: Handle any conversion between formats */
    
    sync_in_progress = false;
    
    return -ENOSYS;
}

/**
 * @brief Synchronize state from Matter to heat pump
 * 
 * Reads Matter attribute changes and updates heat pump settings
 * 
 * @return 0 on success, negative errno on failure
 */
int state_sync_matter_to_hp(void)
{
    if (sync_in_progress) {
        LOG_WRN("Sync already in progress");
        return -EBUSY;
    }
    
    sync_in_progress = true;
    
    /* TODO: Read Matter attribute changes */
    /* TODO: Validate and convert to heat pump format */
    /* TODO: Update heat pump settings */
    /* TODO: Wait for confirmation */
    
    sync_in_progress = false;
    
    return -ENOSYS;
}

/**
 * @brief Periodic sync task
 * 
 * Called periodically to ensure state consistency
 */
void state_sync_periodic(void)
{
    /* TODO: Check if heat pump is connected */
    /* TODO: Perform bidirectional sync if needed */
    /* TODO: Update connection status in Matter */
}
```
